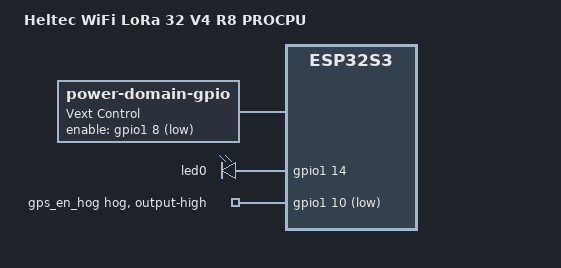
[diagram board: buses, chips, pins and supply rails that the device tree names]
/*
 * Heltec WiFi LoRa 32 (V4 R8) — PROCPU.
 * ESP32-S3 WROOM, 16MB flash + 8MB OCTAL PSRAM, KCT8103L FEM.
 *
 * Reuses the plain-V4 pinctrl and common hardware dtsi, then applies the R8
 * deltas (from firmware variants/esp32s3/heltec_v4_r8/variant.h):
 *   - Vext moves GPIO36 -> GPIO40
 *   - no ADC_CTRL (battery divider is ungated)
 *   - KCT8103L FEM (CTX RX-mode select on GPIO5, same as V4 4.3)
 *   - GPS enable moves to GPIO42; standby line dropped
 * All R8-specific pins are VERIFY(hardware) — nothing here has been confirmed
 * against a board yet, octal-PSRAM bring-up least of all.
 *
 * The PSRAM part itself is configured in this board's Kconfig.defconfig (OCTAL
 * mode, ESPPSRAM64, 80 MHz, 4 MB shared-multi-heap pool), not here and not in an
 * application overlay — see the comment there.
 *
 * SPDX-License-Identifier: Apache-2.0
 */
/dts-v1/;

#include <espressif/esp32s3/esp32s3_wroom_n16r8.dtsi>
#include "../heltec_wifi_lora32_v4/heltec_wifi_lora32_v4-pinctrl.dtsi"
#include <zephyr/dt-bindings/pwm/pwm.h>
#include <espressif/partitions_0x0_amp_16M.dtsi>
#include "../heltec_wifi_lora32_v4/heltec_wifi_lora32_v4-common.dtsi"

/ {
	model = "Heltec WiFi LoRa 32 V4 R8 PROCPU";
	compatible = "espressif,esp32s3";

	/* Vext on GPIO40 (active-low) instead of the plain-V4 GPIO36. */
	vext_ctrl: vext_ctrl {
		compatible = "power-domain-gpio";
		enable-gpios = <&gpio1 8 (GPIO_PULL_UP | GPIO_ACTIVE_LOW)>;	/* GPIO40 */
		#power-domain-cells = <0>;
		label = "Vext Control";
	};
};

/*
 * R8 has no ADC_CTRL gate at all -- confirmed against HTIT-WBR8H_V4.3.2.pdf,
 * where ADC_Ctrl appears nowhere on the sheet and R27 390k / R28 100k sit
 * straight across VBAT (GPIO33-37 are consumed by this board's octal PSRAM).
 * So the divider is permanently connected and reads directly; un-gate it.
 *
 * The common dtsi used to define a separate `adc_ctrl` power-domain node that
 * this file deleted. That node is gone (the gate is now the divider's own
 * `power-gpios` property -- see the comment there), so there is nothing left
 * to delete, only the property to drop.
 */
&vbatt {
	/delete-property/ power-gpios;
};

/*
 * ---------------------------------------------------------------------------
 * GPIO33-37 DO NOT EXIST ON THIS BOARD.
 * ---------------------------------------------------------------------------
 * On an ESP32-S3 fitted with OCTAL PSRAM, GPIO33..37 are consumed by the wider
 * MSPI bus that reaches the PSRAM die (SPIIO4, SPIIO5, SPIIO6, SPIIO7, SPIDQS).
 * They are not merely "in use" by a peripheral we could rehome — the module
 * bonds them to the PSRAM, so anything that muxes them away corrupts every
 * PSRAM access, including the .ext_ram.bss that the NodeDB, config store and
 * PhoneAPI queues live in. The 2 MB QUAD-PSRAM V4 leaves these five pins free,
 * which is precisely why Heltec could use GPIO34/35/36/37 there and had to move
 * all four here.
 *
 * Consequences, all handled in this file:
 *   GPIO34  VGNSS_Ctrl -> GPIO42        (gps_en_hog below; the plain-V4 GPIO34
 *                                        hog lives in that board's own .dts,
 *                                        which this board does not include)
 *   GPIO35  white LED  -> GPIO46        (&led0 and &ledc0_default below)
 *   GPIO36  Vext       -> GPIO40        (vext_ctrl above)
 *   GPIO37  ADC_CTRL   -> gone entirely (&vbatt power-gpios dropped above)
 *
 * Anything added to the shared -common.dtsi / -pinctrl.dtsi in the 33..37 range
 * from now on must be overridden here too.
 */

/*
 * White LED moves GPIO35 -> GPIO46 on R8 (per the Heltec V4-R8 pin map). On the
 * plain V4, GPIO46 is the GC1109 FEM CPS mode pin; R8 fits the KCT8103L (mode on
 * GPIO5), so GPIO46 is free for the LED here. The common.dtsi led0 defaults to
 * GPIO35 — override it. VERIFY(hardware): confirm the LED is on GPIO46 on R8.
 */
&led0 {
	gpios = <&gpio1 14 GPIO_ACTIVE_HIGH>;	/* GPIO46 */
};

/*
 * Move the LEDC output for the PWM LED to GPIO46 as well, so it drives the same
 * LED the gpio-led node does instead of a PSRAM data line.
 *
 * This is a LATENT fault rather than a currently-firing one, which is what makes
 * it worth spelling out. The meshtastic sample builds with CONFIG_PWM=n, so the
 * LEDC driver is not compiled in and never applies its pinctrl state. But ledc0
 * is still status="okay" in the merged devicetree with pinctrl-0 =
 * <&ledc0_default>, so the moment anyone enables CONFIG_PWM on this board (LED
 * brightness, a buzzer, a display backlight) the LEDC driver's init would mux
 * LEDC_LS_SIG_OUT0 onto GPIO35 = SPIIO6 and pull the PSRAM out from under a
 * running system. The symptom would be random corruption of PSRAM-resident
 * structs, not a visibly broken LED — hours of debugging aimed at the wrong
 * subsystem.
 */
&ledc0_default {
	group1 {
		pinmux = <LEDC_CH0_GPIO46>;
	};
};

/*
 * The FEM (KCT8103L on R8) is powered/detected/configured by the shared board C
 * init (../heltec_wifi_lora32_v4/heltec_wifi_lora32_v4_fem.c, compiled via this
 * board's CMakeLists) — no static FEM hogs here. Detection will report KCT8103L.
 */

/* L76K GPS enable on GPIO42 (VERIFY polarity + reset/standby wiring on R8). */
&gpio1 {
	gps_en_hog {
		gpio-hog;
		gpios = <10 GPIO_ACTIVE_LOW>;	/* GPIO42 */
		output-high;
	};
};
